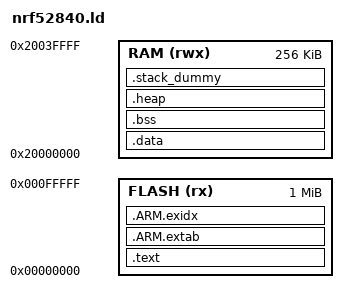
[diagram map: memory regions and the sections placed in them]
/*
 *  Copyright (c) 2016, The OpenThread Authors.
 *  All rights reserved.
 *
 *  Redistribution and use in source and binary forms, with or without
 *  modification, are permitted provided that the following conditions are met:
 *  1. Redistributions of source code must retain the above copyright
 *     notice, this list of conditions and the following disclaimer.
 *  2. Redistributions in binary form must reproduce the above copyright
 *     notice, this list of conditions and the following disclaimer in the
 *     documentation and/or other materials provided with the distribution.
 *  3. Neither the name of the copyright holder nor the
 *     names of its contributors may be used to endorse or promote products
 *     derived from this software without specific prior written permission.
 *
 *  THIS SOFTWARE IS PROVIDED BY THE COPYRIGHT HOLDERS AND CONTRIBUTORS "AS IS"
 *  AND ANY EXPRESS OR IMPLIED WARRANTIES, INCLUDING, BUT NOT LIMITED TO, THE
 *  IMPLIED WARRANTIES OF MERCHANTABILITY AND FITNESS FOR A PARTICULAR PURPOSE
 *  ARE DISCLAIMED. IN NO EVENT SHALL THE COPYRIGHT HOLDER OR CONTRIBUTORS BE
 *  LIABLE FOR ANY DIRECT, INDIRECT, INCIDENTAL, SPECIAL, EXEMPLARY, OR
 *  CONSEQUENTIAL DAMAGES (INCLUDING, BUT NOT LIMITED TO, PROCUREMENT OF
 *  SUBSTITUTE GOODS OR SERVICES; LOSS OF USE, DATA, OR PROFITS; OR BUSINESS
 *  INTERRUPTION) HOWEVER CAUSED AND ON ANY THEORY OF LIABILITY, WHETHER IN
 *  CONTRACT, STRICT LIABILITY, OR TORT (INCLUDING NEGLIGENCE OR OTHERWISE)
 *  ARISING IN ANY WAY OUT OF THE USE OF THIS SOFTWARE, EVEN IF ADVISED OF THE
 *  POSSIBILITY OF SUCH DAMAGE.
 */

/**
 * @file
 *   GCC linker script for nRF52840.
 */

SEARCH_DIR(.)
GROUP(-lgcc -lc -lnosys)

MEMORY
{
  FLASH (rx) : ORIGIN = 0x00000000, LENGTH = 0x100000
  RAM (rwx) :  ORIGIN = 0x20000000, LENGTH = 0x40000
}

OUTPUT_FORMAT ("elf32-littlearm", "elf32-bigarm", "elf32-littlearm")

ENTRY(Reset_Handler)

FLASH_PAGE_SIZE       = 4096;
FLASH_DATA_PAGES_USED = 4;

SECTIONS
{
    .text :
    {
        KEEP(*(.isr_vector))
        *(.text*)

        KEEP(*(.init))
        KEEP(*(.fini))

        /* .ctors */
        *crtbegin.o(.ctors)
        *crtbegin?.o(.ctors)
        *(EXCLUDE_FILE(*crtend?.o *crtend.o) .ctors)
        *(SORT(.ctors.*))
        *(.ctors)

        /* .dtors */
        *crtbegin.o(.dtors)
        *crtbegin?.o(.dtors)
        *(EXCLUDE_FILE(*crtend?.o *crtend.o) .dtors)
        *(SORT(.dtors.*))
        *(.dtors)

        *(.rodata*)

        KEEP(*(.eh_frame*))
    } > FLASH

    .ARM.extab :
    {
        *(.ARM.extab* .gnu.linkonce.armextab.*)
    } > FLASH

    __exidx_start = .;
    .ARM.exidx :
    {
        *(.ARM.exidx* .gnu.linkonce.armexidx.*)
    } > FLASH
    __exidx_end = .;

    __etext = .;

    .data : AT (__etext)
    {
        __data_start__ = .;
        *(vtable)
        *(.data*)

        . = ALIGN(4);
        /* preinit data */
        PROVIDE_HIDDEN (__preinit_array_start = .);
        KEEP(*(.preinit_array))
        PROVIDE_HIDDEN (__preinit_array_end = .);

        . = ALIGN(4);
        /* init data */
        PROVIDE_HIDDEN (__init_array_start = .);
        KEEP(*(SORT(.init_array.*)))
        KEEP(*(.init_array))
        PROVIDE_HIDDEN (__init_array_end = .);


        . = ALIGN(4);
        /* finit data */
        PROVIDE_HIDDEN (__fini_array_start = .);
        KEEP(*(SORT(.fini_array.*)))
        KEEP(*(.fini_array))
        PROVIDE_HIDDEN (__fini_array_end = .);

        KEEP(*(.jcr*))
        . = ALIGN(4);
        /* All data end */
        __data_end__ = .;

    } > RAM

    .bss :
    {
        . = ALIGN(4);
        __bss_start__ = .;
        *(.bss*)
        *(COMMON)
        . = ALIGN(4);
        __bss_end__ = .;
    } > RAM

    .heap (COPY):
    {
        __HeapBase = .;
        __end__ = .;
        PROVIDE(end = .);
        KEEP(*(.heap*))
        __HeapLimit = .;
    } > RAM

    /* .stack_dummy section doesn't contains any symbols. It is only
     * used for linker to calculate size of stack sections, and assign
     * values to stack symbols later */
    .stack_dummy (COPY):
    {
        KEEP(*(.stack*))
    } > RAM

    __stop_ot_flash_data = (ORIGIN(FLASH) + LENGTH(FLASH));
    __start_ot_flash_data = (__stop_ot_flash_data - (FLASH_PAGE_SIZE * FLASH_DATA_PAGES_USED));

    /* Assure that code does not overlap flash data area.*/
    ASSERT((__start_ot_flash_data >= __etext + SIZEOF(.data)), "Error: Code overlaps flash data area.")

    /* Set stack top to end of RAM, and stack limit move down by
     * size of stack_dummy section */
    __StackTop = ORIGIN(RAM) + LENGTH(RAM);
    __StackLimit = __StackTop - SIZEOF(.stack_dummy);
    PROVIDE(__stack = __StackTop);

    /* Check if data + heap + stack exceeds RAM limit */
    ASSERT(__StackLimit >= __HeapLimit, "region RAM overflowed with stack")
}
